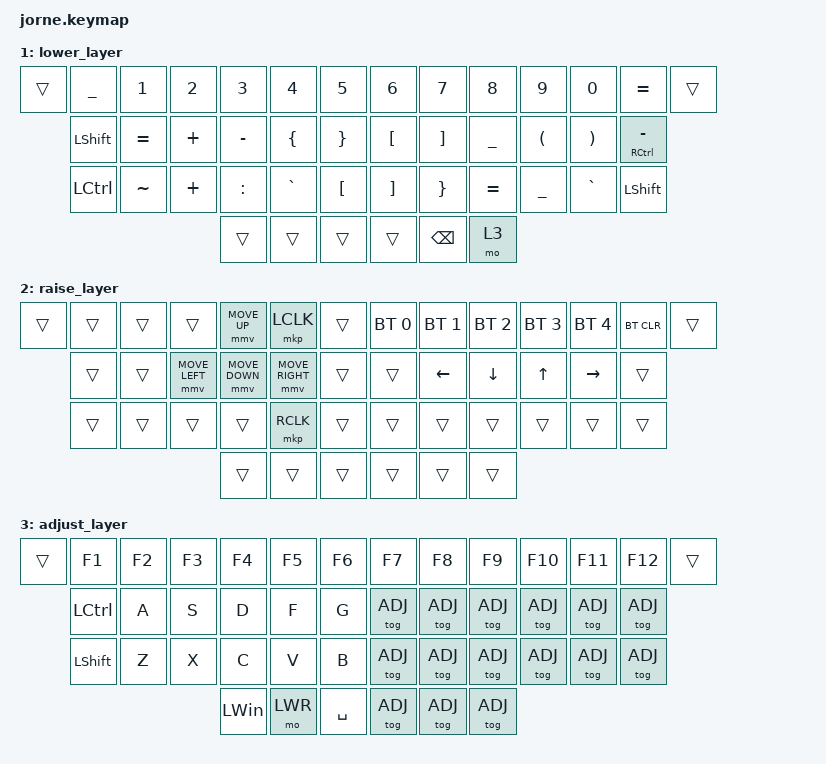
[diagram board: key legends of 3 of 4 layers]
/*
 * Copyright (c) 2020 The ZMK Contributors
 *
 * SPDX-License-Identifier: MIT
 */

#include <dt-bindings/zmk/mouse.h>
#include <behaviors.dtsi>
#include <dt-bindings/zmk/bt.h>
#include <dt-bindings/zmk/keys.h>

#include "../zmk-nodefree-config/helper.h"
#include "mouse.dtsi"
#include "extra_keys.h"

#define DEF 0
#define LWR 1
#define RSE 2
#define ADJ 3

#define KEYS_L LT0 LT1 LT2 LT3 LT4 LM0 LM1 LM2 LM3 LM4 LB0 LB1 LB2 LB3 LB4  // left hand
#define KEYS_R RT0 RT1 RT2 RT3 RT4 RM0 RM1 RM2 RM3 RM4 RB0 RB1 RB2 RB3 RB4  // right hand
#define THUMBS LH2 LH1 LH0 RH0 RH1 RH2                                      // thumbs

#define MAKE_HRM(NAME, HOLD, TAP, TRIGGER_POS) \
    ZMK_BEHAVIOR(NAME, hold_tap, \
        flavor = "balanced"; \
        tapping-term-ms = <280>; \
        quick-tap-ms = <QUICK_TAP_MS>; \
        require-prior-idle-ms = <150>; \
        bindings = <HOLD>, <TAP>; \
        hold-trigger-key-positions = <TRIGGER_POS>; \
        hold-trigger-on-release; \
    )
MAKE_HRM(hml, &kp, &kp, KEYS_R THUMBS)  // left-hand HRMs
MAKE_HRM(hmr, &kp, &kp, KEYS_L THUMBS)



/ {
    keymap {
        compatible = "zmk,keymap";

        default_layer {
            // -----------------------------------------------------------------------------------------
            // |  RSE |   ~       |  Q  |  W  |  E  |  R  |  T  |   |  Y  |  U   |  I  |  O  |  P  |  [   |     |
            //        | SHFT/Tab  |  A  |  S  |  D  |  F  |  G  |   |  H  |  J   |  K  |  L  |  ;  |  '   |
            //        | CTRL      |  Z  |  X  |  C  |  V  |  B  |   |  N  |  M   |  ,  |  .  |  /  | RALT |
            //                           | GUI | LWR | SPC |   | RET | BKSP | RSE |

            bindings = <
&lt RSE ESC  &kp ESC         &kp Q         &kp W          &kp E          &kp R           &kp T            &kp Y   &kp U          &kp I          &kp O        &kp P          &kp LBKT            &trans
             &mt LSHIFT TAB  &hml LGUI A   &hml LALT S    &hml LCTRL D   &hml LSHIFT F   &kp G            &kp H   &hmr RSHIFT J  &hmr LCTRL K   &hmr LALT L  &kp LGUI SEMI  &kp SQT
             &kp LCTRL       &kp Z         &kp X          &kp C          &kp V           &kp B            &kp N   &kp M          &kp COMMA      &kp DOT      &kp FSLH       &mt RALT BACKSLASH
                                              &kp LWIN  &mo LWR  &lt RSE SPACE                               &lt LWR RET  &kp BSPC  &kp DEL
            >;
        };

        lower_layer {
            // -----------------------------------------------------------------------------------------
            // |     |  _  |  1  |  2  |  3  |  4  |  5  |   |  6  |  7  |  8  |  9  |  0  | = |     |
            //       |  +  |  !  |  @  |  #  |  $  |  %  |   |  ^  |  &  |  *  |  (  |  )  |  -  |
            //       | SHFT | ~  |  +  |  -  |  {  |  [  |   |  ]  |  }  |  =  |  _  |  `  |SHFT |
            //                    |    |     |    |   |    |     |    |

            bindings = <
&trans  &kp UNDER         &kp N1     &kp N2    &kp N3     &kp N4          &kp N5              &kp N6             &kp N7             &kp N8     &kp N9          &kp N0     &kp EQUAL        &trans
        &kp LEFT_SHIFT    &kp EQUAL  &kp PLUS  &kp MINUS  &kp LEFT_BRACE  &kp RIGHT_BRACE     &kp LEFT_BRACKET   &kp RIGHT_BRACKET  &kp UNDER  &kp LPAR        &kp RPAR   &mt RCTRL MINUS
        &kp LEFT_CONTROL  &kp TILDE  &kp PLUS  &kp COLON  &kp GRAVE       &kp LEFT_BRACKET    &kp RIGHT_BRACKET  &kp RIGHT_BRACE    &kp EQUAL  &kp UNDERSCORE  &kp GRAVE  &kp LSHFT
                                               &trans     &trans          &trans              &trans             &kp BACKSPACE      &mo 3
            >;
        };

        raise_layer {
            // -----------------------------------------------------------------------------------------
            // |     |        |     |         |  M_UP   |            |        |      |     |       |     |     |     |     |     |
            //       |        |     | M_LEFT  |  M_DOWN |  M_RIGHT   |        |  LEFT| DOWN|  UP   |RIGHT|     |     |     |
            //       |        |     |         |         |  M_RCLICK  |        |      |     |       |     |     |     |     |
            //                                |     | M_LCLICK | |      |     |        |     |

            bindings = <
&trans  &trans  &trans  &trans          &mmv MOVE_UP    &mkp LCLK        &trans    &bt BT_SEL 0  &bt BT_SEL 1  &bt BT_SEL 2  &bt BT_SEL 3  &bt BT_SEL 4  &bt BT_CLR  &trans
        &trans  &trans  &mmv MOVE_LEFT  &mmv MOVE_DOWN  &mmv MOVE_RIGHT  &trans    &trans        &kp LEFT      &kp DOWN      &kp UP        &kp RIGHT     &trans
        &trans  &trans  &trans          &trans          &mkp RCLK        &trans    &trans        &trans        &trans        &trans        &trans        &trans
                                        &trans          &trans           &trans    &trans        &trans        &trans
            >;
        };

        adjust_layer {
            // -----------------------------------------------------------------------------------------
            // |  RSE |   ~       |  Q  |  W  |  E  |  R  |  T  |   |  Y  |  U   |  I  |  O  |  P  |  [   |     |
            //        | CTRL/Tab  |  A  |  S  |  D  |  F  |  G  |   |  H  |  J   |  K  |  L  |  ;  |  '   |
            //        | SHFT      |  Z  |  X  |  C  |  V  |  B  |   |  N  |  M   |  ,  |  .  |  /  | RALT |
            //                           | GUI | LWR | RET |   | SPC | BKSP | RSE |

            bindings = <
&trans  &kp F1     &kp F2  &kp F3  &kp F4    &kp F5   &kp F6       &kp F7    &kp F8    &kp F9    &kp F10   &kp F11   &kp F12   &trans
        &kp LCTRL  &kp A   &kp S   &kp D     &kp F    &kp G        &tog ADJ  &tog ADJ  &tog ADJ  &tog ADJ  &tog ADJ  &tog ADJ
        &kp LSHFT  &kp Z   &kp X   &kp C     &kp V    &kp B        &tog ADJ  &tog ADJ  &tog ADJ  &tog ADJ  &tog ADJ  &tog ADJ
                                   &kp LWIN  &mo LWR  &kp SPACE    &tog ADJ  &tog ADJ  &tog ADJ
            >;
        };
    };
};
